AUTOSAR XML (schema 4-2-1)
package /ComponentTypes
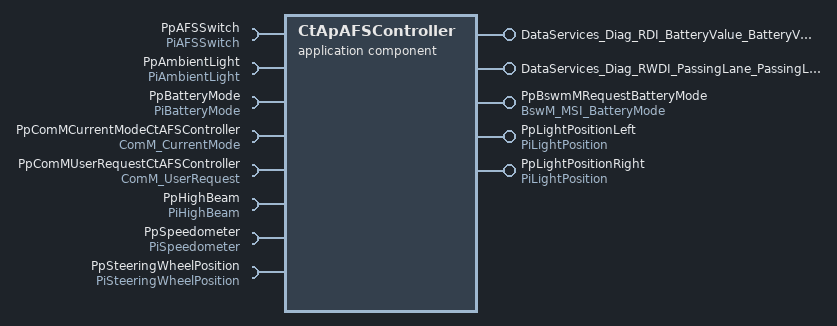
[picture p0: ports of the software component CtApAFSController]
  application sw component type CtApAFSController
    5 x provide port:
      DataServices_Diag_RDI_BatteryValue_BatteryValue: provided-com-specs=[{operation=ConditionCheckRead, queue-length=1}, {operation=ReadData, queue-length=1}], provided-interface=DataServices_Diag_RDI_BatteryValue_BatteryValue
      DataServices_Diag_RWDI_PassingLane_PassingLane_PassingLane: provided-interface=DataServices_Diag_RWDI_PassingLane_PassingLane_PassingLane
        provided-com-specs:
          operation=ConditionCheckRead, queue-length=1
          operation=ReadData, queue-length=1
          operation=WriteData, queue-length=1
      PpBswmMRequestBatteryMode: mode-switch-sender-com-spec{enhanced-mode-api=false, mode-group=BswM_MDGP_BatteryMode, queue-length=1}, provided-interface=BswM_MSI_BatteryMode
      PpLightPositionLeft: provided-com-specs=[{data-element=DeLightLength, init-value=0}, {data-element=DeLightPosition, init-value=0}], provided-interface=PiLightPosition
      PpLightPositionRight: provided-interface=PiLightPosition
        provided-com-specs:
          data-element=DeLightLength, init-value=0
          data-element=DeLightPosition, init-value=constant-reference=CDarkLight
    8 x require port:
      PpAFSSwitch: required-interface=PiAFSSwitch
      PpAmbientLight: nonqueued-receiver-com-spec{data-element=DeAmbientLight, filter=data-filter-type=ALWAYS, init-value=constant-reference=CDarkLight}, required-interface=PiAmbientLight
      PpBatteryMode: mode-switch-receiver-com-spec{enhanced-mode-api=false, supports-asynchronous-mode-switch=false}, required-interface=PiBatteryMode
      PpComMCurrentModeCtAFSController: mode-switch-receiver-com-spec{enhanced-mode-api=false, supports-asynchronous-mode-switch=false}, required-interface=ComM_CurrentMode
      PpComMUserRequestCtAFSController: required-interface=ComM_UserRequest
      PpHighBeam: required-interface=PiHighBeam
      PpSpeedometer: nonqueued-receiver-com-spec{data-element=DeSpeedometer, filter=data-filter-type=ALWAYS, init-value=constant-reference=CInitSpeed}, required-interface=PiSpeedometer
      PpSteeringWheelPosition: nonqueued-receiver-com-spec{data-element=DeSteeringWheelPosition, filter=data-filter-type=ALWAYS, init-value=0}, required-interface=PiSteeringWheelPosition
    behavior CtApAFSController_InternalBehavior
      exclusive area ExclusiveArea
      5 x operation invoked event:
        OIT_DataServices_Diag_RDI_BatteryValue_BatteryValue_ConditionCheckRead_DataServices_Diag_RDI_BatteryValue_BatteryValue_C3B28864A: start-on-event=DataServices_Diag_RDI_BatteryValue_BatteryValue_ConditionCheckRead, operation=DataServices_Diag_RDI_BatteryValue_BatteryValue.ConditionCheckRead
        OIT_DataServices_Diag_RDI_BatteryValue_BatteryValue_ReadData_DataServices_Diag_RDI_BatteryValue_BatteryValue_ReadData: start-on-event=DataServices_Diag_RDI_BatteryValue_BatteryValue_ReadData, operation=DataServices_Diag_RDI_BatteryValue_BatteryValue.ReadData
        OIT_DataServices_Diag_RWDI_PassingLane_PassingLane_PassingLane_ConditionCheckRead_DataServices_Diag_RWDI_PassingLane_Pas5F15AC2B: start-on-event=DataServices_Diag_RWDI_PassingLane_PassingLane_PassingLane_ConditionCheckRead, operation=DataServices_Diag_RWDI_PassingLane_PassingLane_PassingLane.ConditionCheckRead
        OIT_DataServices_Diag_RWDI_PassingLane_PassingLane_PassingLane_ReadData_DataServices_Diag_RWDI_PassingLane_PassingLane_P8D71540F: start-on-event=DataServices_Diag_RWDI_PassingLane_PassingLane_PassingLane_ReadData, operation=DataServices_Diag_RWDI_PassingLane_PassingLane_PassingLane.ReadData
        OIT_DataServices_Diag_RWDI_PassingLane_PassingLane_PassingLane_WriteData_DataServices_Diag_RWDI_PassingLane_PassingLane_DA0BE9C4: start-on-event=DataServices_Diag_RWDI_PassingLane_PassingLane_PassingLane_WriteData, operation=DataServices_Diag_RWDI_PassingLane_PassingLane_PassingLane.WriteData
      init event CtApAFSController_InitEvent: start-on-event=RCtApAFSController_Init
      swc mode switch event MST_RCtApAFSControllerComM_FULL_COMM_Exit_0: start-on-event=RCtApAFSControllerComM_FULL_COMM_Exit, activation=ON-EXIT, mode=PpComMCurrentModeCtAFSController.currentMode.COMM_FULL_COMMUNICATION
      swc mode switch event MST_RCtApAFSControllerComM_ModeChange_FULL_COM_Entry_0: disabled-mode=[PpBatteryMode.BatteryMode.BATTERY_HIGH, PpBatteryMode.BatteryMode.BATTERY_MEDIUM], start-on-event=RCtApAFSControllerComM_ModeChange_FULL_COM_Entry, activation=ON-ENTRY, mode=PpBatteryMode.BatteryMode.BATTERY_LOW
      data received event DRT_RCtApAFSControllerLogic_PpSteeringWheelPosition_DeSteeringWheelPosition: disabled-mode=PpBatteryMode.BatteryMode.BATTERY_LOW, start-on-event=RCtApAFSControllerLogic, data=PpSteeringWheelPosition.DeSteeringWheelPosition
      9 x runnable:
        DataServices_Diag_RDI_BatteryValue_BatteryValue_ConditionCheckRead
        DataServices_Diag_RDI_BatteryValue_BatteryValue_ReadData
        DataServices_Diag_RWDI_PassingLane_PassingLane_PassingLane_ConditionCheckRead
        DataServices_Diag_RWDI_PassingLane_PassingLane_PassingLane_ReadData: can-enter-exclusive-area=ExclusiveArea
        DataServices_Diag_RWDI_PassingLane_PassingLane_PassingLane_WriteData: can-enter-exclusive-area=ExclusiveArea
        RCtApAFSController_Init: can-enter-exclusive-area=ExclusiveArea
        RCtApAFSControllerComM_FULL_COMM_Exit
        RCtApAFSControllerComM_ModeChange_FULL_COM_Entry
        RCtApAFSControllerLogic: mode-access-point=PpBatteryMode.BatteryMode
          data-receive-point-by-arguments:
            access REC_PpAmbientLight_DeAmbientLight: accessed-variable=PpAmbientLight.DeAmbientLight
            access REC_PpSpeedometer_DeSpeedometer: accessed-variable=PpSpeedometer.DeSpeedometer
            access REC_PpSteeringWheelPosition_DeSteeringWheelPosition: accessed-variable=PpSteeringWheelPosition.DeSteeringWheelPosition
          data-send-points:
            4 x access:
              SEND_PpLightPosition_DeLightPosition: accessed-variable=PpLightPositionLeft.DeLightPosition
              SEND_PpLightPositionLeft_DeLightMode: accessed-variable=PpLightPositionLeft.DeLightLength
              SEND_PpLightPositionRight_DeLightMode: accessed-variable=PpLightPositionRight.DeLightLength
              SEND_PpLightPositionRight_DeLightPosition: accessed-variable=PpLightPositionRight.DeLightPosition
          sync call SC_PpAFSSwitch_ReadChannel: operation=PpAFSSwitch.ReadChannel, timeout=0
          sync call SC_PpComMUserRequestCtAFSController_RequestComMode: operation=PpComMUserRequestCtAFSController.RequestComMode, timeout=0
          sync call SC_PpHighBeam_ReadChannel: operation=PpHighBeam.ReadChannel, timeout=0
  swc implementation CtApAFSController_Implementation: behavior=CtApAFSController_InternalBehavior
    code-descriptors:
      code Default: artifact-descriptors=autosar-engineering-object={short-label=Default, category=SWSRC}
